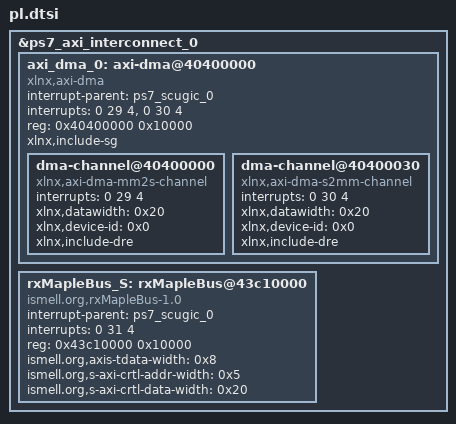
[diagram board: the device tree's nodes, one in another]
/*
 * CAUTION: This file is automatically generated by Xilinx.
 * Version: HSM 2014.2
 * Today is: Thu Jan 15 20:09:29 2015
*/

	&ps7_axi_interconnect_0 {
		ranges;
		axi_dma_0: axi-dma@40400000 {
			compatible = "xlnx,axi-dma";
			interrupt-parent = <&ps7_scugic_0>;
			interrupts = <0 29 4>, <0 30 4>;
			reg = <0x40400000 0x10000>;
			xlnx,include-sg;
			/*xlnx,sg-include-stscntrl-strm;*/
			dma-channel@40400000 {
				compatible = "xlnx,axi-dma-mm2s-channel";
				interrupts = <0 29 4>;
				xlnx,datawidth = <0x20>;
				xlnx,device-id = <0x0>;
				xlnx,include-dre;
			} ;
			dma-channel@40400030 {
				compatible = "xlnx,axi-dma-s2mm-channel";
				interrupts = <0 30 4>;
				xlnx,datawidth = <0x20>;
				xlnx,device-id = <0x0>;
				xlnx,include-dre;
			} ;
		} ;
		rxMapleBus_S: rxMapleBus@43c10000 {
			compatible = "ismell.org,rxMapleBus-1.0";
			interrupt-parent = <&ps7_scugic_0>;
			interrupts = <0 31 4>;
			reg = <0x43c10000 0x10000>;
			ismell.org,axis-tdata-width = <0x8>;
			ismell.org,s-axi-crtl-addr-width = <0x5>;
			ismell.org,s-axi-crtl-data-width = <0x20>;
		} ;
	} ;
